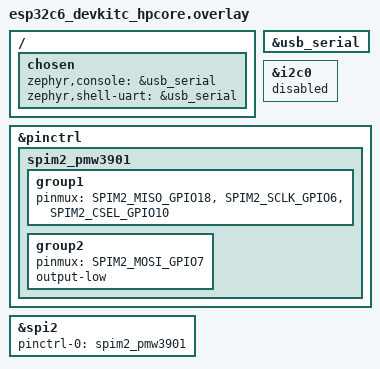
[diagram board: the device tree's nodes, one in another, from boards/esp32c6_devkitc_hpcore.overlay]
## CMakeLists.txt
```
# SPDX-License-Identifier: Apache-2.0

cmake_minimum_required(VERSION 3.20.0)

find_package(Zephyr REQUIRED HINTS $ENV{ZEPHYR_BASE})
project(pmw3901_test)

target_sources(app PRIVATE src/main.c src/pmw3901.c)
```

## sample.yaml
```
sample:
  description: Test PMW3901 optical flow sensor connection
  name: pmw3901 test
common:
  tags: spi sensor optical-flow
  integration_platforms:
    - esp32c6_devkitc_hpcore
  harness: console
  harness_config:
    type: one_line
    regex:
      - "PMW3901.*initialized successfully"
tests:
  sample.riskybird.pmw3901_test:
    tags: spi sensor optical-flow
    platform_allow: esp32c6_devkitc_hpcore
```

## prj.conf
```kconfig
CONFIG_SPI=y
CONFIG_GPIO=y

# Enable float support in printf (picolibc)
CONFIG_PICOLIBC_IO_FLOAT=y

# Logging
# CONFIG_LOG=y
# CONFIG_LOG_DEFAULT_LEVEL=4

# Console / early debug
CONFIG_STDOUT_CONSOLE=y
CONFIG_LOG_MODE_IMMEDIATE=y
CONFIG_LOG_PRINTK=y
CONFIG_PRINTK=y
CONFIG_EARLY_CONSOLE=y

# # Better crash info on RISC-V
# CONFIG_EXCEPTION_DEBUG=y
# CONFIG_ASSERT=y
# CONFIG_ASSERT_VERBOSE=y
```

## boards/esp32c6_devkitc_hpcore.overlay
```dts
/*
 * SPDX-License-Identifier: Apache-2.0
 *
 * PMW3901 bring-up overlay (SPI2 pinmux)
 *
 * Pin mapping (riskybird PCB):
 * - SCK:  GPIO6
 * - MOSI: GPIO7
 * - MISO: GPIO18
 * - CS:   GPIO19  (handled as a normal GPIO in software; not hardware CSEL)
 * - RST:  GPIO2   (optional, active-low)
 * - LED:  GPIO3   (optional, active-low)
 *
 * This overlay reconfigures SPI2 pinmux to match the PMW3901 wiring.
 */

/* Route console to the ESP32-C6 built-in USB Serial/JTAG so the chip-ID result prints on the
 * riskybird USB-C port (/dev/ttyACM*). Without this the hpcore board sends console to UART0
 * physical pins, which are not broken out -- the PMW3901 test output would go nowhere. */
/ {
	chosen {
		zephyr,console = &usb_serial;
		zephyr,shell-uart = &usb_serial;
	};
};

&usb_serial {
	status = "okay";
};

/* Disable I2C0 to avoid pin conflict with GPIO6/GPIO7 (board default I2C0). */
&i2c0 {
	status = "disabled";
};

&pinctrl {
	spim2_pmw3901: spim2_pmw3901 {
		group1 {
			pinmux = <SPIM2_MISO_GPIO18>,
				 <SPIM2_SCLK_GPIO6>,
				 <SPIM2_CSEL_GPIO10>;
		};

		group2 {
			pinmux = <SPIM2_MOSI_GPIO7>;
			output-low;
		};
	};
};

&spi2 {
	status = "okay";
	pinctrl-0 = <&spim2_pmw3901>;
	pinctrl-names = "default";
};
```

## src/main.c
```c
/*
 * SPDX-License-Identifier: Apache-2.0
 * 
 * PMW3901 Optical Flow Sensor Test
 * 
 * This sample initializes and tests the PMW3901 optical flow sensor
 * connected via SPI.
 */

#include <zephyr/kernel.h>
#include <zephyr/device.h>
#include <zephyr/drivers/spi.h>
#include <zephyr/drivers/gpio.h>
#include <stdio.h>
#include <stdint.h>
#include <errno.h>

#include "pmw3901.h"
#include <zephyr/devicetree.h>

/* Get SPI device from device tree */
#if IS_ENABLED(CONFIG_SPI_BITBANG)
#define SPI_NODE DT_NODELABEL(pmw3901_spi)
#else
#define SPI_NODE DT_NODELABEL(spi2)
#endif

/* GPIO device - ESP32C6 uses gpio0 */
#define GPIO_NODE DT_NODELABEL(gpio0)

/* GPIO pin numbers - defined in overlay */
#define CS_GPIO_PIN    19
#define RESET_GPIO_PIN 2
#define LED_GPIO_PIN   3

/* Device configuration and data structures - initialized at runtime */
static struct pmw3901_config pmw3901_cfg;
static struct pmw3901_data pmw3901_data;

/* Create a simple device structure */
static const struct device pmw3901_device = {
    .name = "PMW3901",
    .config = &pmw3901_cfg,
    .data = &pmw3901_data,
};

#define PMW3901_DEV (&pmw3901_device)

/* Initialize PMW3901 configuration at runtime */
static int pmw3901_init_config(void)
{
    const struct device *spi_dev;
    const struct device *gpio_dev;

    /* Get devices - these should exist if device tree is correct */
    if (!DT_NODE_EXISTS(SPI_NODE)) {
        printf("ERROR: SPI2 node does not exist in device tree\n");
        return -ENODEV;
    }
    if (!DT_NODE_EXISTS(GPIO_NODE)) {
        printf("ERROR: GPIO0 node does not exist in device tree\n");
        return -ENODEV;
    }

    spi_dev = DEVICE_DT_GET(SPI_NODE);
    gpio_dev = DEVICE_DT_GET(GPIO_NODE);

    if (spi_dev == NULL || gpio_dev == NULL) {
        printf("ERROR: Failed to get device pointers\n");
        return -ENODEV;
    }

    pmw3901_cfg.spi.bus = spi_dev;
    /* PMW3901 uses SPI mode 3 (CPOL=1, CPHA=1) */
    pmw3901_cfg.spi.config.operation =
        SPI_WORD_SET(8) | SPI_OP_MODE_MASTER | SPI_MODE_CPOL | SPI_MODE_CPHA | SPI_TRANSFER_MSB;
    pmw3901_cfg.spi.config.frequency = 2000000;  /* 2MHz */
    pmw3901_cfg.spi.config.slave = 0;

    pmw3901_cfg.cs_gpio.port = gpio_dev;
    pmw3901_cfg.cs_gpio.pin = CS_GPIO_PIN;
    pmw3901_cfg.cs_gpio.dt_flags = GPIO_ACTIVE_LOW;

    /* riskybird v3: the PMW3901 (IC1) NRESET is tied high through R37 (no GPIO reset), and its
     * MOTION line goes to the FPGA SoM (JB2.73), not the ESP32-C6 -- so there is no reset/LED GPIO
     * on this board. Leave both NULL; the driver guards on .port and does a SOFTWARE power-on-reset
     * (reg 0x3A=0x5A) + polled reads, so the chip-ID connection test still works over SPI alone.
     * SPI itself is a shared bus (ESP via 100R R63-66, FPGA via 47R R27-29/34) -- the FPGA must be
     * off/high-Z for the ESP to master it (true during bring-up). */
    pmw3901_cfg.reset_gpio.port = NULL;
    pmw3901_cfg.led_gpio.port = NULL;

    return 0;
}

int main(void)
{
    int ret;
    motionBurst_t motion;
    int16_t deltaX, deltaY;

    printf("PMW3901 Optical Flow Sensor Test\n");
    printf("================================\n\n");

    /* Initialize PMW3901 configuration */
    ret = pmw3901_init_config();
    if (ret != 0) {
        printf("ERROR: Failed to initialize PMW3901 configuration (ret: %d)\n", ret);
        return 1;
    }

    /* Check if SPI and GPIO devices are ready */
    if (!device_is_ready(pmw3901_cfg.spi.bus)) {
        printf("ERROR: SPI device is not ready\n");
        return 1;
    }
    if (!device_is_ready(pmw3901_cfg.cs_gpio.port)) {
        printf("ERROR: GPIO device is not ready\n");
        return 1;
    }

    printf("SPI and GPIO devices ready\n\n");

    /* Initialize the PMW3901 sensor. Retry in a loop: pmw3901_init() prints the chip ID on every
     * attempt (0x49/0xB6 = alive, 0xFF = open/not-wetted, 0x00 = MISO low), so the connection
     * status is ALWAYS visible on the serial monitor no matter when it attaches -- no need to catch
     * a one-shot boot print or fight the USB-JTAG reset. */
    printf("Initializing PMW3901 (looping chip-ID probe until connected)...\n");
    while (pmw3901_init(PMW3901_DEV) != 0) {
        k_msleep(700);
    }
    printf("PMW3901 initialized successfully.\n\n");

    /* --- throughput benchmark: time back-to-back motion-burst reads (SPI @ 2 MHz) --- */
    {
        const int N = 2000;
        uint32_t c0 = k_cycle_get_32();
        for (int i = 0; i < N; i++) {
            pmw3901_read_motion_burst(PMW3901_DEV, &motion);
        }
        uint32_t us = k_cyc_to_us_floor32(k_cycle_get_32() - c0);
        printf("BENCH: %d motion-burst reads in %u us -> %.2f us/read, %.0f Hz max (SPI 2MHz)\n\n",
               N, us, (double)us / N, N * 1e6 / (double)us);
    }

    /* Continuously read motion data */
    printf("Entering continuous motion read loop...\n");
    printf("Format: deltaX, deltaY, SQUAL, Shutter\n\n");

    while (1) {
        /* Read motion burst */
        ret = pmw3901_read_motion_burst(PMW3901_DEV, &motion);
        if (ret != 0) {
            printf("ERROR: Failed to read motion burst (ret: %d)\n", ret);
        } else {
            printf("Motion: deltaX=%5d, deltaY=%5d, SQUAL=%3u, Shutter=%5u",
                   motion.deltaX, motion.deltaY, motion.squal, motion.shutter);
            
            if (motion.motionOccured) {
                printf(" [MOTION]");
            }
            printf("\n");
        }

        /* Also read motion count for comparison */
        ret = pmw3901_read_motion_count(PMW3901_DEV, &deltaX, &deltaY);
        if (ret == 0) {
            printf("  Count: deltaX=%5d, deltaY=%5d\n", deltaX, deltaY);
        }

        k_msleep(100); /* Poll every 100ms */
    }

    return 0;
}
```

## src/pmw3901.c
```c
/*
 * SPDX-License-Identifier: Apache-2.0
 * 
 * PMW3901 Optical Flow Sensor Driver Implementation
 * Ported from ESP-IDF to Zephyr
 */

#include "pmw3901.h"
#include <zephyr/logging/log.h>
#include <string.h>

LOG_MODULE_REGISTER(pmw3901, CONFIG_LOG_DEFAULT_LEVEL);

/*
 * gpio_dt_spec values are LOGICAL, not raw electrical levels:
 * - value=1 means "active" (asserted)
 * - value=0 means "inactive" (deasserted)
 *
 * Since our CS is configured GPIO_ACTIVE_LOW, asserting CS drives the pin low.
 */
static void cs_deassert(const struct device *dev)
{
    const struct pmw3901_config *config = dev->config;
    gpio_pin_set_dt(&config->cs_gpio, 0);
}

static void cs_assert(const struct device *dev)
{
    const struct pmw3901_config *config = dev->config;
    gpio_pin_set_dt(&config->cs_gpio, 1);
}

static void busy_wait_us(int microseconds)
{
    k_busy_wait(microseconds);
}

uint8_t pmw3901_register_read(const struct device *dev, uint8_t reg)
{
    const struct pmw3901_config *config = dev->config;
    uint8_t data = 0;
    uint8_t tx_data = reg & ~0x80u;  /* Set MSB to 0 for read */
    uint8_t dummy = 0;

    struct spi_buf tx_buf = {
        .buf = &tx_data,
        .len = 1,
    };
    struct spi_buf_set tx_bufs = {
        .buffers = &tx_buf,
        .count = 1,
    };

    struct spi_buf rx_buf = {
        .buf = &data,
        .len = 1,
    };
    struct spi_buf_set rx_bufs = {
        .buffers = &rx_buf,
        .count = 1,
    };

    cs_assert(dev);
    busy_wait_us(50);

    /* Send register address */
    spi_write_dt(&config->spi, &tx_bufs);
    busy_wait_us(500);  /* Longer delay after sending register address */

    /* Read data (send dummy byte) */
    tx_buf.buf = &dummy;
    spi_transceive_dt(&config->spi, &tx_bufs, &rx_bufs);

    busy_wait_us(50);
    cs_deassert(dev);
    k_msleep(1);

    return data;
}

int pmw3901_register_write(const struct device *dev, uint8_t reg, uint8_t value)
{
    const struct pmw3901_config *config = dev->config;
    uint8_t data[2] = { (uint8_t)(reg | 0x80u), value };  /* Set MSB to 1 for write */

    struct spi_buf tx_buf = {
        .buf = data,
        .len = 2,
    };
    struct spi_buf_set tx_bufs = {
        .buffers = &tx_buf,
        .count = 1,
    };

    cs_assert(dev);
    busy_wait_us(50);

    spi_write_dt(&config->spi, &tx_bufs);

    busy_wait_us(50);
    cs_deassert(dev);
    k_msleep(1);

    return 0;
}

static void init_registers(const struct device *dev)
{
    pmw3901_register_write(dev, 0x7F, 0x00);
    pmw3901_register_write(dev, 0x61, 0xAD);
    pmw3901_register_write(dev, 0x7F, 0x03);
    pmw3901_register_write(dev, 0x40, 0x00);
    pmw3901_register_write(dev, 0x7F, 0x05);
    pmw3901_register_write(dev, 0x41, 0xB3);
    pmw3901_register_write(dev, 0x43, 0xF1);
    pmw3901_register_write(dev, 0x45, 0x14);
    pmw3901_register_write(dev, 0x5B, 0x32);
    pmw3901_register_write(dev, 0x5F, 0x34);
    pmw3901_register_write(dev, 0x7B, 0x08);
    pmw3901_register_write(dev, 0x7F, 0x06);
    pmw3901_register_write(dev, 0x44, 0x1B);
    pmw3901_register_write(dev, 0x40, 0xBF);
    pmw3901_register_write(dev, 0x4E, 0x3F);
    pmw3901_register_write(dev, 0x7F, 0x08);
    pmw3901_register_write(dev, 0x65, 0x20);
    pmw3901_register_write(dev, 0x6A, 0x18);
    pmw3901_register_write(dev, 0x7F, 0x09);
    pmw3901_register_write(dev, 0x4F, 0xAF);
    pmw3901_register_write(dev, 0x5F, 0x40);
    pmw3901_register_write(dev, 0x48, 0x80);
    pmw3901_register_write(dev, 0x49, 0x80);
    pmw3901_register_write(dev, 0x57, 0x77);
    pmw3901_register_write(dev, 0x60, 0x78);
    pmw3901_register_write(dev, 0x61, 0x78);
    pmw3901_register_write(dev, 0x62, 0x08);
    pmw3901_register_write(dev, 0x63, 0x50);
    pmw3901_register_write(dev, 0x7F, 0x0A);
    pmw3901_register_write(dev, 0x45, 0x60);
    pmw3901_register_write(dev, 0x7F, 0x00);
    pmw3901_register_write(dev, 0x4D, 0x11);
    pmw3901_register_write(dev, 0x55, 0x80);
    pmw3901_register_write(dev, 0x74, 0x1F);
    pmw3901_register_write(dev, 0x75, 0x1F);
    pmw3901_register_write(dev, 0x4A, 0x78);
    pmw3901_register_write(dev, 0x4B, 0x78);
    pmw3901_register_write(dev, 0x44, 0x08);
    pmw3901_register_write(dev, 0x45, 0x50);
    pmw3901_register_write(dev, 0x64, 0xFF);
    pmw3901_register_write(dev, 0x65, 0x1F);
    pmw3901_register_write(dev, 0x7F, 0x14);
    pmw3901_register_write(dev, 0x65, 0x67);
    pmw3901_register_write(dev, 0x66, 0x08);
    pmw3901_register_write(dev, 0x63, 0x70);
    pmw3901_register_write(dev, 0x7F, 0x15);
    pmw3901_register_write(dev, 0x48, 0x48);
    pmw3901_register_write(dev, 0x7F, 0x07);
    pmw3901_register_write(dev, 0x41, 0x0D);
    pmw3901_register_write(dev, 0x43, 0x14);
    pmw3901_register_write(dev, 0x4B, 0x0E);
    pmw3901_register_write(dev, 0x45, 0x0F);
    pmw3901_register_write(dev, 0x44, 0x42);
    pmw3901_register_write(dev, 0x4C, 0x80);
    pmw3901_register_write(dev, 0x7F, 0x10);
    pmw3901_register_write(dev, 0x5B, 0x02);
    pmw3901_register_write(dev, 0x7F, 0x07);
    pmw3901_register_write(dev, 0x40, 0x41);
    pmw3901_register_write(dev, 0x70, 0x00);

    k_msleep(10);

    pmw3901_register_write(dev, 0x32, 0x44);
    pmw3901_register_write(dev, 0x7F, 0x07);
    pmw3901_register_write(dev, 0x40, 0x40);
    pmw3901_register_write(dev, 0x7F, 0x06);
    pmw3901_register_write(dev, 0x62, 0xF0);
    pmw3901_register_write(dev, 0x63, 0x00);
    pmw3901_register_write(dev, 0x7F, 0x0D);
    pmw3901_register_write(dev, 0x48, 0xC0);
    pmw3901_register_write(dev, 0x6F, 0xD5);
    pmw3901_register_write(dev, 0x7F, 0x00);
    pmw3901_register_write(dev, 0x5B, 0xA0);
    pmw3901_register_write(dev, 0x4E, 0xA8);
    pmw3901_register_write(dev, 0x5A, 0x50);
    pmw3901_register_write(dev, 0x40, 0x80);

    pmw3901_register_write(dev, 0x7F, 0x00);
    pmw3901_register_write(dev, 0x5A, 0x10);
    pmw3901_register_write(dev, 0x54, 0x00);
}

int pmw3901_init(const struct device *dev)
{
    const struct pmw3901_config *config = dev->config;
    struct pmw3901_data *data = dev->data;
    uint8_t chip_id, inv_chip_id;

    if (!spi_is_ready_dt(&config->spi)) {
        LOG_ERR("SPI device not ready");
        return -ENODEV;
    }

    if (!gpio_is_ready_dt(&config->cs_gpio)) {
        LOG_ERR("CS GPIO not ready");
        return -ENODEV;
    }

    /* Configure CS pin */
    gpio_pin_configure_dt(&config->cs_gpio, GPIO_OUTPUT_INACTIVE);

    /* Configure optional reset pin if present */
    if (config->reset_gpio.port) {
        if (!gpio_is_ready_dt(&config->reset_gpio)) {
            LOG_ERR("Reset GPIO not ready");
            return -ENODEV;
        }
        gpio_pin_configure_dt(&config->reset_gpio, GPIO_OUTPUT_INACTIVE);
        /* Reset sequence: assert (active-low), then deassert */
        gpio_pin_set_dt(&config->reset_gpio, 1);
        k_msleep(10);
        gpio_pin_set_dt(&config->reset_gpio, 0);
        k_msleep(10);
    }

    /* Configure optional LED pin if present */
    if (config->led_gpio.port) {
        if (gpio_is_ready_dt(&config->led_gpio)) {
            gpio_pin_configure_dt(&config->led_gpio, GPIO_OUTPUT_INACTIVE);
        }
    }

    k_msleep(40);

    /* CS toggle sequence */
    cs_deassert(dev);
    k_msleep(2);
    cs_assert(dev);
    k_msleep(2);
    cs_deassert(dev);
    k_msleep(2);
    cs_assert(dev);
    k_msleep(2);

    /* Read chip ID */
    chip_id = pmw3901_register_read(dev, 0x00);
    inv_chip_id = pmw3901_register_read(dev, 0x5F);

    /* Use printk so this is visible even when CONFIG_LOG is disabled */
    printk("PMW3901 chip ID: 0x%02X, inverted: 0x%02X\n", chip_id, inv_chip_id);

    if (chip_id == 0x49 || inv_chip_id == 0xB6) {
        /* Power on reset */
        pmw3901_register_write(dev, 0x3A, 0x5A);
        k_msleep(5);

        /* Read motion registers once */
        pmw3901_register_read(dev, 0x02);
        pmw3901_register_read(dev, 0x03);
        pmw3901_register_read(dev, 0x04);
        pmw3901_register_read(dev, 0x05);
        pmw3901_register_read(dev, 0x06);
        k_msleep(1);

        /* Initialize registers */
        init_registers(dev);

        /* Verify chip ID again */
        chip_id = pmw3901_register_read(dev, 0x00);
        inv_chip_id = pmw3901_register_read(dev, 0x5F);
        LOG_INF("PMW3901 chip ID after init: 0x%02X, inverted: 0x%02X", chip_id, inv_chip_id);

        data->last_read_time_us = k_uptime_get() * 1000;
        return 0;
    }

    printk("PMW3901: invalid chip ID (check pinmux MISO/MOSI/SCK, CS wiring, SPI mode)\n");
    return -ENODEV;
}

int pmw3901_read_motion_burst(const struct device *dev, motionBurst_t *motion)
{
    const struct pmw3901_config *config = dev->config;
    uint8_t address = 0x16;
    uint8_t rx_buffer[sizeof(motionBurst_t)] = {0};

    struct spi_buf tx_buf = {
        .buf = &address,
        .len = 1,
    };
    struct spi_buf_set tx_bufs = {
        .buffers = &tx_buf,
        .count = 1,
    };

    struct spi_buf rx_buf = {
        .buf = rx_buffer,
        .len = sizeof(motionBurst_t),
    };
    struct spi_buf_set rx_bufs = {
        .buffers = &rx_buf,
        .count = 1,
    };

    cs_assert(dev);
    k_msleep(1);

    /* Send address */
    spi_write_dt(&config->spi, &tx_bufs);
    k_msleep(1);

    /* Read motion burst data */
    spi_read_dt(&config->spi, &rx_bufs);

    cs_deassert(dev);
    k_msleep(1);

    memcpy(motion, rx_buffer, sizeof(motionBurst_t));

    /* Fix endianness for shutter value */
    uint16_t real_shutter = (motion->shutter >> 8) & 0x0FF;
    real_shutter |= (motion->shutter & 0x0FF) << 8;
    motion->shutter = real_shutter;

    return 0;
}

int pmw3901_read_motion_count(const struct device *dev, int16_t *deltaX, int16_t *deltaY)
{
    pmw3901_register_read(dev, 0x02);
    *deltaY = -1 * (((int16_t)pmw3901_register_read(dev, 0x04) << 8) | pmw3901_register_read(dev, 0x03));
    *deltaX = -1 * (((int16_t)pmw3901_register_read(dev, 0x06) << 8) | pmw3901_register_read(dev, 0x05));
    return 0;
}
```

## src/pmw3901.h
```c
/*
 * SPDX-License-Identifier: Apache-2.0
 * 
 * PMW3901 Optical Flow Sensor Driver
 * Ported from ESP-IDF to Zephyr
 */

#ifndef PMW3901_H
#define PMW3901_H

#include <zephyr/kernel.h>
#include <zephyr/device.h>
#include <zephyr/drivers/spi.h>
#include <zephyr/drivers/gpio.h>
#include <stdint.h>

typedef struct motionBurst_s {
    union {
        uint8_t motion;
        struct {
            uint8_t frameFrom0    : 1;
            uint8_t runMode       : 2;
            uint8_t reserved1     : 1;
            uint8_t rawFrom0      : 1;
            uint8_t reserved2     : 2;
            uint8_t motionOccured : 1;
        };
    };

    uint8_t observation;
    int16_t deltaX;
    int16_t deltaY;

    uint8_t squal;

    uint8_t rawDataSum;
    uint8_t maxRawData;
    uint8_t minRawData;

    uint16_t shutter;
} __attribute__((packed)) motionBurst_t;

struct pmw3901_config {
    struct spi_dt_spec spi;
    struct gpio_dt_spec cs_gpio;
    struct gpio_dt_spec reset_gpio;  /* Optional: CamRST pin (active low) */
    struct gpio_dt_spec led_gpio;    /* Optional: LED_N pin */
};

struct pmw3901_data {
    int64_t last_read_time_us;
};

int pmw3901_init(const struct device *dev);
int pmw3901_read_motion_burst(const struct device *dev, motionBurst_t *motion);
int pmw3901_read_motion_count(const struct device *dev, int16_t *deltaX, int16_t *deltaY);
uint8_t pmw3901_register_read(const struct device *dev, uint8_t reg);
int pmw3901_register_write(const struct device *dev, uint8_t reg, uint8_t value);

#endif // PMW3901_H
```
